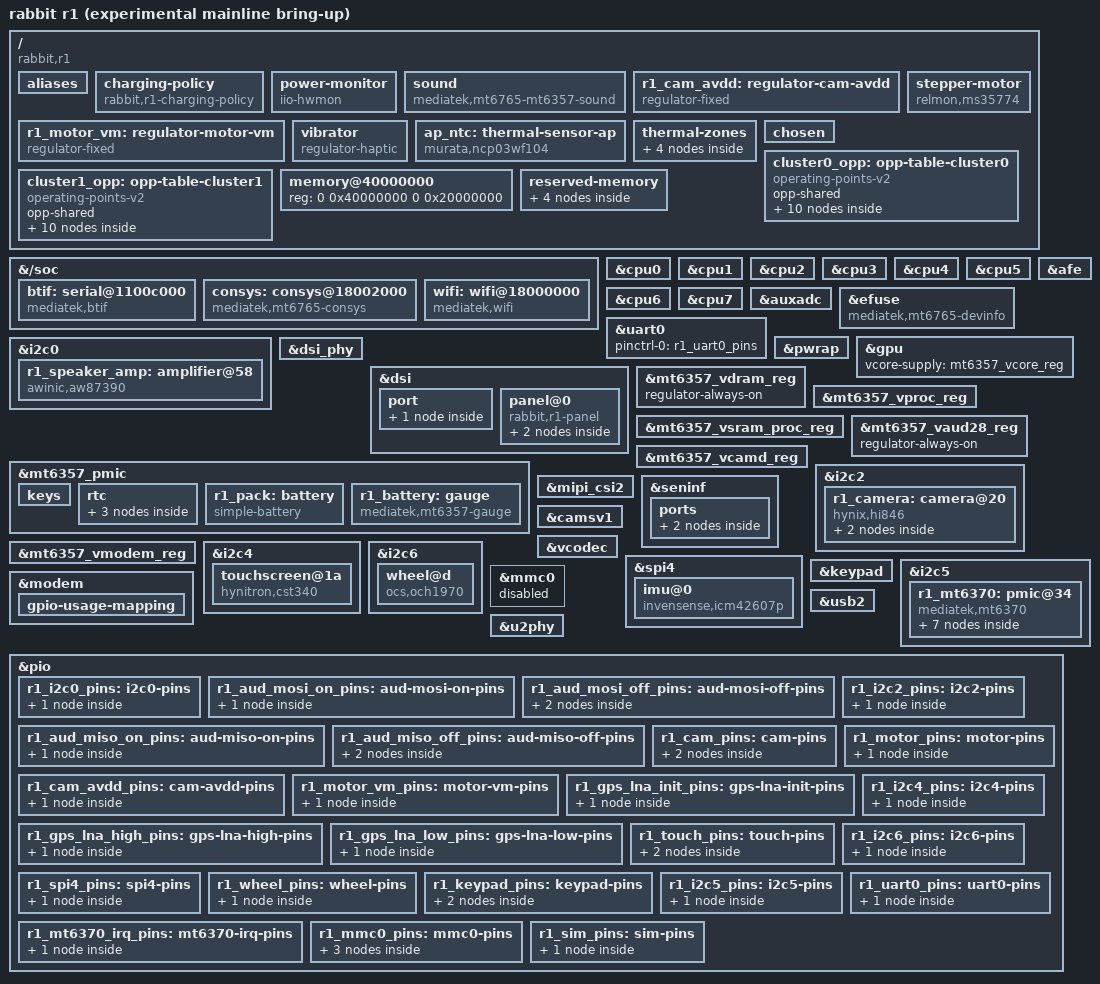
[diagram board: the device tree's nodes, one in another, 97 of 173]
// SPDX-License-Identifier: (GPL-2.0-only OR MIT)
/*
 * Experimental rabbit r1 bring-up tree. NOT hardware validated.
 * Board wiring: rabbit-hmi-oss r1 source and RabbitOS v0.8.293 DT/DTBO.
 * Pin groups follow the MT6765 port's Nokia ROO example where the SoC
 * muxes agree with Rabbit's gpio_init_default table.
 *
 * The stock loader must populate actual RAM and firmware carve-outs.
 * The memory entry below is the stock DT's 512 MiB placeholder, NOT an
 * assertion that the device has only 512 MiB. Inspect the live FDT before
 * relying on it. Do not apply the stock vendor overlay to this tree.
 */

/dts-v1/;

#include <dt-bindings/gpio/gpio.h>
#include <dt-bindings/iio/adc/mediatek,mt6357-auxadc.h>
#include <dt-bindings/iio/adc/mediatek,mt6370_adc.h>
#include <dt-bindings/input/input.h>
#include <dt-bindings/pinctrl/mediatek,mt6765-pinfunc.h>
#include "mt6765.dtsi"
#include "mt6357.dtsi"

/ {
	model = "rabbit r1 (experimental mainline bring-up)";
	compatible = "rabbit,r1", "mediatek,mt6765";
	chassis-type = "handset";

	aliases {
		i2c4 = &i2c4;
		i2c5 = &i2c5;
		mmc0 = &mmc0;
	};

	charging-policy {
		compatible = "rabbit,r1-charging-policy";
		charger-supply = <&r1_charger>;
		battery-supply = <&r1_battery>;
		usb-gadget-supply = <&usb2>;
		/* Experimental, source-backed policy; physical charging is untested. */
	};

	power-monitor {
		compatible = "iio-hwmon";
		io-channels = <&r1_mt6370_adc MT6370_CHAN_VBUSDIV5>,
			      <&r1_mt6370_adc MT6370_CHAN_VSYS>,
			      <&r1_mt6370_adc MT6370_CHAN_VBAT>,
			      <&r1_mt6370_adc MT6370_CHAN_IBUS>,
			      <&r1_mt6370_adc MT6370_CHAN_IBAT>,
			      <&r1_mt6370_adc MT6370_CHAN_TEMP_JC>;
	};

	/*
	 * Stock audio: MT6765 AFE -> MTKAIF -> MT6357 codec. The speaker is an
	 * AW87390 class-K amplifier (I2C0 0x58) on the MT6357 line output; the
	 * stock codec driver turns its "Music" profile on with the LOL path.
	 * No 3.5 mm jack: MT6357 headphone outputs and ACCDET are unused.
	 */
	sound {
		compatible = "mediatek,mt6765-mt6357-sound";
		model = "rabbit-r1";
		mediatek,platform = <&afe>;
		mediatek,speaker-amplifier = <&r1_speaker_amp>;
		pinctrl-names = "aud_mosi_off", "aud_mosi_on",
				"aud_miso_off", "aud_miso_on";
		pinctrl-0 = <&r1_aud_mosi_off_pins>;
		pinctrl-1 = <&r1_aud_mosi_on_pins>;
		pinctrl-2 = <&r1_aud_miso_off_pins>;
		pinctrl-3 = <&r1_aud_miso_on_pins>;
	};

	/*
	 * Stock imgsensor powers the main camera's AVDD from an external
	 * 2.8 V LDO enabled by GPIO165 (cam0_vcama_on), not from MT6357
	 * VCAMA. The stock sequence waits 5 ms after each rail.
	 */
	r1_cam_avdd: regulator-cam-avdd {
		compatible = "regulator-fixed";
		regulator-name = "cam-avdd";
		regulator-min-microvolt = <2800000>;
		regulator-max-microvolt = <2800000>;
		gpio = <&pio 165 GPIO_ACTIVE_HIGH>;
		enable-active-high;
		startup-delay-us = <5000>;
		pinctrl-names = "default";
		pinctrl-0 = <&r1_cam_avdd_pins>;
	};

	/*
	 * Camera rotation ("rabbit eye"): MS35774 stepper driver. Stock
	 * step_motor_ms35774 switches the motor supply with GPIO163 and waits
	 * 10 ms before enabling the outputs; PDN is held low and MS1/MS2 at
	 * high/low throughout.
	 */
	r1_motor_vm: regulator-motor-vm {
		compatible = "regulator-fixed";
		regulator-name = "motor-vm";
		gpio = <&pio 163 GPIO_ACTIVE_HIGH>;
		enable-active-high;
		startup-delay-us = <10000>;
		pinctrl-names = "default";
		pinctrl-0 = <&r1_motor_vm_pins>;
	};

	stepper-motor {
		compatible = "relmon,ms35774";
		vm-supply = <&r1_motor_vm>;
		enable-gpios = <&pio 166 GPIO_ACTIVE_LOW>;
		dir-gpios = <&pio 167 GPIO_ACTIVE_HIGH>;
		step-gpios = <&pio 168 GPIO_ACTIVE_HIGH>;
		powerdown-gpios = <&pio 164 GPIO_ACTIVE_HIGH>;
		mode-gpios = <&pio 171 GPIO_ACTIVE_HIGH>,
			     <&pio 170 GPIO_ACTIVE_HIGH>;
		pinctrl-names = "default";
		pinctrl-0 = <&r1_motor_pins>;
	};

	/*
	 * Stock drives the motor from VIBR at 2.3 - 3.2 V (regulator-vibrator);
	 * VIBR's steps in that range are 2.8 and 3.0 V.
	 */
	vibrator {
		compatible = "regulator-haptic";
		haptic-supply = <&mt6357_vibr_reg>;
		min-microvolt = <2800000>;
		max-microvolt = <3000000>;
	};

	/*
	 * Board NTC next to the SoC on AUXADC channel 0, the stock "mtktsAP"
	 * sensor: a 100 kOhm NCP15WF104F03RC to ground under a 390 kOhm pull-up
	 * to 1.8 V (thermal.conf tzbts_param: PUP_R 390000, PUP_VOLT 1800,
	 * NTC_TABLE 7; DT thermal-sensor1 on auxadc channel 0). The NCP03WF104
	 * is the same WF104 part in a smaller package; the driver's table for it
	 * matches the stock table 7 entry for entry.
	 */
	ap_ntc: thermal-sensor-ap {
		compatible = "murata,ncp03wf104";
		io-channels = <&auxadc 0>;
		pullup-uv = <1800000>;
		pullup-ohm = <390000>;
		pulldown-ohm = <0>;
		#thermal-sensor-cells = <0>;
	};

	thermal-zones {
		/*
		 * The stock policy limits charging from 45 C here and turns the
		 * camera off from 53 C. These trips only report the crossings
		 * to userspace: the reading is not validated on hardware, so
		 * nothing in the kernel acts on it yet.
		 */
		ap_ntc_thermal: ap-ntc-thermal {
			polling-delay-passive = <1000>;
			polling-delay = <2000>;
			thermal-sensors = <&ap_ntc>;

			trips {
				ap_ntc_warm: trip-warm {
					temperature = <45000>;
					hysteresis = <2000>;
					type = "passive";
				};

				ap_ntc_hot: trip-hot {
					temperature = <53000>;
					hysteresis = <2000>;
					type = "passive";
				};
			};
		};
	};

	chosen {
		stdout-path = "serial0:921600n8";
		/*
		 * The stock ATF offers PSCI SYSTEM_SUSPEND, but it runs SPM
		 * firmware that only the stock kernel hands over: sleep to idle.
		 */
		bootargs = "earlycon=uart8250,mmio32,0x11002000 console=ttyS0,921600n8 clk_ignore_unused regulator_ignore_unused mem_sleep_default=s2idle";
	};

	/*
	 * CPU DVFS. Vproc (MT6357 VPROC) and Vsram_proc feed both clusters and
	 * the CCI. Pairs are the stock R1 kernel's CPU level 10 tables: efuse
	 * segment (devinfo word 30, efuse_segment_cell @0x78) reads 0x24 here,
	 * which _mt_cpufreq_get_cpu_level maps to level 10 ("65X"). Tables in
	 * out/stock-kernel.elf: L 0xffffff80097d4498, LL 0xffffff80097d4a18,
	 * CCI 0xffffff80097d4f98 (opp_tbls at 0xffffff80097d5018).
	 *
	 * LK leaves L 1500 MHz, LL 920 MHz and CCI 600 MHz at 0.800 V. CCI is
	 * not scaled; the stock CCI table needs 0.8125 V for 600 MHz, so no OPP
	 * below 0.8125 V is listed. OPPs above 0.85 V are turbo-mode: they stay
	 * unused until /sys/devices/system/cpu/cpufreq/boost is set to 1, as
	 * the thermal throttling in mt6765.dtsi is not validated on hardware.
	 */
	cluster0_opp: opp-table-cluster0 {
		compatible = "operating-points-v2";
		opp-shared;

		opp-1617000000 {
			opp-hz = /bits/ 64 <1617000000>;
			opp-microvolt = <812500>;
		};

		opp-1750000000 {
			opp-hz = /bits/ 64 <1750000000>;
			opp-microvolt = <850000>;
		};

		opp-1803000000 {
			opp-hz = /bits/ 64 <1803000000>;
			opp-microvolt = <893750>;
			turbo-mode;
		};

		opp-1856000000 {
			opp-hz = /bits/ 64 <1856000000>;
			opp-microvolt = <937500>;
			turbo-mode;
		};

		opp-1909000000 {
			opp-hz = /bits/ 64 <1909000000>;
			opp-microvolt = <975000>;
			turbo-mode;
		};

		opp-1962000000 {
			opp-hz = /bits/ 64 <1962000000>;
			opp-microvolt = <1018750>;
			turbo-mode;
		};

		opp-2015000000 {
			opp-hz = /bits/ 64 <2015000000>;
			opp-microvolt = <1056250>;
			turbo-mode;
		};

		opp-2068000000 {
			opp-hz = /bits/ 64 <2068000000>;
			opp-microvolt = <1100000>;
			turbo-mode;
		};

		opp-2130000000 {
			opp-hz = /bits/ 64 <2130000000>;
			opp-microvolt = <1150000>;
			turbo-mode;
		};

		opp-2200000000 {
			opp-hz = /bits/ 64 <2200000000>;
			opp-microvolt = <1200000>;
			turbo-mode;
		};
	};

	cluster1_opp: opp-table-cluster1 {
		compatible = "operating-points-v2";
		opp-shared;

		opp-948000000 {
			opp-hz = /bits/ 64 <948000000>;
			opp-microvolt = <812500>;
		};

		opp-1050000000 {
			opp-hz = /bits/ 64 <1050000000>;
			opp-microvolt = <850000>;
		};

		opp-1114000000 {
			opp-hz = /bits/ 64 <1114000000>;
			opp-microvolt = <893750>;
			turbo-mode;
		};

		opp-1179000000 {
			opp-hz = /bits/ 64 <1179000000>;
			opp-microvolt = <937500>;
			turbo-mode;
		};

		opp-1244000000 {
			opp-hz = /bits/ 64 <1244000000>;
			opp-microvolt = <975000>;
			turbo-mode;
		};

		opp-1309000000 {
			opp-hz = /bits/ 64 <1309000000>;
			opp-microvolt = <1018750>;
			turbo-mode;
		};

		opp-1374000000 {
			opp-hz = /bits/ 64 <1374000000>;
			opp-microvolt = <1056250>;
			turbo-mode;
		};

		opp-1439000000 {
			opp-hz = /bits/ 64 <1439000000>;
			opp-microvolt = <1100000>;
			turbo-mode;
		};

		opp-1515000000 {
			opp-hz = /bits/ 64 <1515000000>;
			opp-microvolt = <1150000>;
			turbo-mode;
		};

		opp-1600000000 {
			opp-hz = /bits/ 64 <1600000000>;
			opp-microvolt = <1200000>;
			turbo-mode;
		};
	};

	/* LK's /memory lookup accepts this unit address and updates the reg. */
	memory@40000000 {
		device_type = "memory";
		reg = <0 0x40000000 0 0x20000000>;
	};

	/* Dynamic reservations copied from the stock base tree. Their final
	 * addresses, plus loader-added TEE/modem reservations, need live-FDT
	 * verification. Remote processors are not enabled by this board file.
	 */
	reserved-memory {
		#address-cells = <2>;
		#size-cells = <2>;
		ranges;

		reserve-memory-sspm_share {
			compatible = "mediatek,reserve-memory-sspm_share";
			no-map;
			size = <0 0x510000>;
			alignment = <0 0x10000>;
			alloc-ranges = <0 0x40000000 0 0x60000000>;
		};

		reserve-memory-scp_share {
			compatible = "mediatek,reserve-memory-scp_share";
			no-map;
			size = <0 0x300000>;
			alignment = <0 0x1000000>;
			alloc-ranges = <0 0x40000000 0 0x50000000>;
		};

		consys_mem: consys-reserve-memory {
			compatible = "mediatek,consys-reserve-memory";
			no-map;
			size = <0 0x400000>;
			alignment = <0 0x1000000>;
			alloc-ranges = <0 0x40000000 0 0x80000000>;
		};

		wifi_mem: wifi-reserve-memory {
			compatible = "shared-dma-pool";
			no-map;
			size = <0 0x300000>;
			alignment = <0 0x1000000>;
			alloc-ranges = <0 0x40000000 0 0x80000000>;
		};
	};
};

/*
 * Connectivity (WiFi/BT/GPS CONSYS, CONNAC1 "soc1_0") for the vendor
 * WMT/BTIF/gen4m drivers in drivers/staging/mtk-connectivity. Addresses,
 * interrupts and register order follow the stock DT; the "conn" scpsys
 * clock of the vendor kernel is the CONN power domain here.
 */
&{/soc} {
	btif: serial@1100c000 {
		compatible = "mediatek,btif";
		/* BTIF, then the AP DMA Tx and Rx channels it owns */
		reg = <0 0x1100c000 0 0x1000>,
		      <0 0x11000880 0 0x80>,
		      <0 0x11000900 0 0x80>;
		interrupts = <GIC_SPI 112 IRQ_TYPE_LEVEL_LOW>,
			     <GIC_SPI 132 IRQ_TYPE_LEVEL_LOW>,
			     <GIC_SPI 133 IRQ_TYPE_LEVEL_LOW>;
		clocks = <&infracfg CLK_IFR_BTIF>,
			 <&infracfg CLK_IFR_AP_DMA>;
		clock-names = "btifc", "apdmac";
	};

	consys: consys@18002000 {
		compatible = "mediatek,mt6765-consys";
		/*
		 * The driver maps these by index: CONN MCU, TOPRGU, INFRACFG_AO,
		 * SPM, CONN_HIF_ON, TOP_MISC_OFF, CFG_ON, CIRQ, TOP_MISC_ON,
		 * HIF_PDMA, AP_PCCIF4 (unused, empty), INFRA_AO_PERICFG (unused)
		 * and INFRACFG for the bus debug dump. The stock DT stopped one
		 * entry short, which left the debug dump with a NULL base.
		 */
		reg = <0 0x18002000 0 0x1000>,
		      <0 0x10007000 0 0x100>,
		      <0 0x10001000 0 0x1000>,
		      <0 0x10006000 0 0x1000>,
		      <0 0x18007000 0 0x1000>,
		      <0 0x180b1000 0 0x1000>,
		      <0 0x180a3000 0 0x1000>,
		      <0 0x180a5000 0 0x800>,
		      <0 0x180c1000 0 0x1000>,
		      <0 0x18004000 0 0x1000>,
		      <0 0 0 0>,
		      <0 0x1020e000 0 0x1000>,
		      <0 0x1020e000 0 0x1000>;
		interrupts = <GIC_SPI 267 IRQ_TYPE_LEVEL_LOW>,
			     <GIC_SPI 269 IRQ_TYPE_LEVEL_LOW>,
			     <GIC_SPI 270 IRQ_TYPE_EDGE_RISING>;
		power-domains = <&spm MT6765_POWER_DOMAIN_CONN>;
		memory-region = <&consys_mem>;
		/*
		 * WMT drives the external GPS LNA enable through these states
		 * while the GPS function is on. The driver takes the LNA pin
		 * number from the first state after "default".
		 */
		pinctrl-names = "default", "gps_lna_state_init",
				"gps_lna_state_oh", "gps_lna_state_ol";
		pinctrl-0 = <&r1_gps_lna_init_pins>;
		pinctrl-1 = <&r1_gps_lna_init_pins>;
		pinctrl-2 = <&r1_gps_lna_high_pins>;
		pinctrl-3 = <&r1_gps_lna_low_pins>;
		pmic = <&mt6357_pmic>;
		vcn18-supply = <&mt6357_vcn18_reg>;
		vcn28-supply = <&mt6357_vcn28_reg>;
		vcn33_bt-supply = <&mt6357_vcn33_bt_reg>;
		vcn33_wifi-supply = <&mt6357_vcn33_wifi_reg>;
	};

	wifi: wifi@18000000 {
		compatible = "mediatek,wifi";
		reg = <0 0x18000000 0 0x100000>;
		interrupts = <GIC_SPI 268 IRQ_TYPE_LEVEL_LOW>;
		memory-region = <&wifi_mem>;
	};
};

&cpu0 {
	clocks = <&mcucfg CLK_MCU_MP0_SEL>,
		 <&topckgen CLK_TOP_ARMPLL_DIVIDER_PLL1_EN>;
	clock-names = "cpu", "intermediate";
	operating-points-v2 = <&cluster0_opp>;
	proc-supply = <&mt6357_vproc_reg>;
	sram-supply = <&mt6357_vsram_proc_reg>;
};

&cpu1 {
	clocks = <&mcucfg CLK_MCU_MP0_SEL>,
		 <&topckgen CLK_TOP_ARMPLL_DIVIDER_PLL1_EN>;
	clock-names = "cpu", "intermediate";
	operating-points-v2 = <&cluster0_opp>;
	proc-supply = <&mt6357_vproc_reg>;
	sram-supply = <&mt6357_vsram_proc_reg>;
};

&cpu2 {
	clocks = <&mcucfg CLK_MCU_MP0_SEL>,
		 <&topckgen CLK_TOP_ARMPLL_DIVIDER_PLL1_EN>;
	clock-names = "cpu", "intermediate";
	operating-points-v2 = <&cluster0_opp>;
	proc-supply = <&mt6357_vproc_reg>;
	sram-supply = <&mt6357_vsram_proc_reg>;
};

&cpu3 {
	clocks = <&mcucfg CLK_MCU_MP0_SEL>,
		 <&topckgen CLK_TOP_ARMPLL_DIVIDER_PLL1_EN>;
	clock-names = "cpu", "intermediate";
	operating-points-v2 = <&cluster0_opp>;
	proc-supply = <&mt6357_vproc_reg>;
	sram-supply = <&mt6357_vsram_proc_reg>;
};

&cpu4 {
	clocks = <&mcucfg CLK_MCU_MP1_SEL>,
		 <&topckgen CLK_TOP_ARMPLL_DIVIDER_PLL1_EN>;
	clock-names = "cpu", "intermediate";
	operating-points-v2 = <&cluster1_opp>;
	proc-supply = <&mt6357_vproc_reg>;
	sram-supply = <&mt6357_vsram_proc_reg>;
};

&cpu5 {
	clocks = <&mcucfg CLK_MCU_MP1_SEL>,
		 <&topckgen CLK_TOP_ARMPLL_DIVIDER_PLL1_EN>;
	clock-names = "cpu", "intermediate";
	operating-points-v2 = <&cluster1_opp>;
	proc-supply = <&mt6357_vproc_reg>;
	sram-supply = <&mt6357_vsram_proc_reg>;
};

&cpu6 {
	clocks = <&mcucfg CLK_MCU_MP1_SEL>,
		 <&topckgen CLK_TOP_ARMPLL_DIVIDER_PLL1_EN>;
	clock-names = "cpu", "intermediate";
	operating-points-v2 = <&cluster1_opp>;
	proc-supply = <&mt6357_vproc_reg>;
	sram-supply = <&mt6357_vsram_proc_reg>;
};

&cpu7 {
	clocks = <&mcucfg CLK_MCU_MP1_SEL>,
		 <&topckgen CLK_TOP_ARMPLL_DIVIDER_PLL1_EN>;
	clock-names = "cpu", "intermediate";
	operating-points-v2 = <&cluster1_opp>;
	proc-supply = <&mt6357_vproc_reg>;
	sram-supply = <&mt6357_vsram_proc_reg>;
};

&auxadc {
	status = "okay";
};

/*
 * The eFuse controller reads as zero once the secure boot chain has run;
 * serve the cells (thermal calibration, socinfo) from LK's devinfo copy.
 */
&efuse {
	compatible = "mediatek,mt6765-devinfo";
};

&uart0 {
	pinctrl-names = "default";
	pinctrl-0 = <&r1_uart0_pins>;
	status = "okay";
};

&pwrap {
	status = "okay";
};

&afe {
	status = "okay";
};

&i2c0 {
	pinctrl-names = "default";
	pinctrl-0 = <&r1_i2c0_pins>;
	/* Stock runs 400 kHz open drain; standard speed for bring-up. */
	clock-frequency = <100000>;
	status = "okay";

	/* Stock aw87xxx_pa@58, dev_index 0; its ACF names the part AW87390. */
	r1_speaker_amp: amplifier@58 {
		compatible = "awinic,aw87390";
		reg = <0x58>;
		#sound-dai-cells = <0>;
		awinic,audio-channel = <0>;
	};
};

&gpu {
	vcore-supply = <&mt6357_vcore_reg>;
	status = "okay";
};

&dsi_phy {
	status = "okay";
};

&dsi {
	status = "okay";

	port {
		r1_dsi_out: endpoint {
			remote-endpoint = <&r1_panel_in>;
		};
	};

	panel@0 {
		compatible = "rabbit,r1-panel";
		reg = <0>;
		reset-gpios = <&pio 45 GPIO_ACTIVE_LOW>;
		backlight = <&r1_backlight>;

		port {
			r1_panel_in: endpoint {
				remote-endpoint = <&r1_dsi_out>;
			};
		};
	};
};

&mt6357_pmic {
	interrupt-controller;
	interrupt-parent = <&pio>;
	interrupts = <144 IRQ_TYPE_LEVEL_HIGH>;
	#interrupt-cells = <2>;

	/*
	 * Stock: only PWRKEY, the side push-to-talk button, as KEY_POWER;
	 * home key commented out. Long-press PMIC reset on PWRKEY, delay 0.
	 */
	keys {
		mediatek,long-press-mode = <1>;
		power-off-time-sec = <0>;

		/delete-node/ key-home;
	};

	rtc {
		nvmem-layout {
			compatible = "fixed-layout";
			#address-cells = <1>;
			#size-cells = <1>;

			/* Raw stock retained bytes; neither is a validated SOC seed. */
			r1_fg_init: initialization@0 {
				reg = <0 1>;
			};

			r1_fg_soc: state-of-charge@1 {
				reg = <1 1>;
			};
		};
	};

	/*
	 * Stock battery_cv is 4.4 V (a high-voltage cell) and the factory
	 * 25 C profile's Qmax is 1010 mAh; the pack is rated 1000 mAh. Alert
	 * temperatures are the stock 0-55 C charging envelope. Charging
	 * limits are the charging policy's, not these.
	 */
	r1_pack: battery {
		compatible = "simple-battery";
		device-chemistry = "lithium-ion";
		charge-full-design-microamp-hours = <1000000>;
		voltage-max-design-microvolt = <4400000>;
		alert-celsius = <0 55>;
	};

	r1_battery: gauge {
		compatible = "mediatek,mt6357-gauge";
		power-supplies = <&r1_charger>;
		monitored-battery = <&r1_pack>;
		/* Stock R_FG_VALUE=10 mOhm, CAR_TUNE_VALUE=100 percent. */
		shunt-resistor-micro-ohms = <10000>;
		mediatek,current-gain-permille = <1000>;
		/* Stock battery voltage is ISENSE, not BATADC. */
		io-channels = <&pmic_adc MT6357_AUXADC_ISENSE>,
			      <&pmic_adc MT6357_AUXADC_BAT_TEMP>,
			      <&pmic_adc MT6357_AUXADC_VBIF>;
		io-channel-names = "battery-voltage", "battery-thermistor", "thermistor-reference";
		mediatek,thermistor-pullup-ohms = <16900>;
		mediatek,thermistor-series-micro-ohms = <10000>;
		/* Active stock 10 kOhm NTC table, also present in v0.8.293's kernel. */
		mediatek,thermistor-resistance-table =
			<(-40000) 195652>, <(-35000) 148171>, <(-30000) 113347>,
			<(-25000) 87559>, <(-20000) 68237>, <(-15000) 53650>,
			<(-10000) 42506>, <(-5000) 33892>, <0 27219>,
			<5000 22021>, <10000 17926>, <15000 14674>,
			<20000 12081>, <25000 10000>, <30000 8315>,
			<35000 6948>, <40000 5834>, <45000 4917>,
			<50000 4161>, <55000 3535>, <60000 3014>;
	};
};

&mt6357_vdram_reg {
	regulator-always-on;
};

/* Stock limits: 1.2 V max (vendor MAX_VPROC_VOLT/MAX_VSRAM_VOLT); LK level as floor. */
&mt6357_vproc_reg {
	regulator-min-microvolt = <800000>;
	regulator-max-microvolt = <1200000>;
};

&mt6357_vsram_proc_reg {
	regulator-min-microvolt = <900000>;
	regulator-max-microvolt = <1200000>;
};

/*
 * The MT6357 codec is an MFD cell without a DT node, so its vaud28 supply
 * resolves to a dummy regulator. Keep the real rail up for the codec.
 */
&mt6357_vaud28_reg {
	regulator-always-on;
};

/* Stock hi846 power table: DVDD 1.2 V from VCAMD, DOVDD 1.8 V from VCAMIO. */
&mt6357_vcamd_reg {
	regulator-min-microvolt = <1200000>;
	regulator-max-microvolt = <1200000>;
};

&i2c2 {
	pinctrl-names = "default";
	pinctrl-0 = <&r1_i2c2_pins>;
	/* Stock runs 400 kHz open drain; standard speed for bring-up. */
	clock-frequency = <100000>;
	status = "okay";

	/*
	 * Main (and only) camera. Stock imgsensor probes hi846_mipi_raw at
	 * 8-bit write ID 0x40, i.e. 7-bit 0x20; the stock DT's camera_main@1a
	 * reg is not used by that driver. PDN (GPIO97) drives XSHUTDOWN and
	 * RST (GPIO101) drives RESETB, both high when the sensor runs. Stock
	 * MCLK is 24 MHz, so the PLL settings here yield 96% of the nominal
	 * 25 MHz link frequencies.
	 */
	r1_camera: camera@20 {
		compatible = "hynix,hi846";
		reg = <0x20>;
		pinctrl-names = "default";
		pinctrl-0 = <&r1_cam_pins>;
		clocks = <&topckgen CLK_TOP_CAMTG_SEL>;
		assigned-clocks = <&topckgen CLK_TOP_CAMTG_SEL>;
		assigned-clock-parents = <&topckgen CLK_TOP_USB20_192M_D8>;
		vdda-supply = <&r1_cam_avdd>;
		vddd-supply = <&mt6357_vcamd_reg>;
		vddio-supply = <&mt6357_vcamio_reg>;
		reset-gpios = <&pio 101 GPIO_ACTIVE_LOW>;
		shutdown-gpios = <&pio 97 GPIO_ACTIVE_LOW>;
		/* Mounted a quarter turn counter-clockwise to the display. */
		rotation = <90>;

		port {
			r1_camera_out: endpoint {
				data-lanes = <1 2 3 4>;
				link-frequencies = /bits/ 64 <80000000 200000000>;
				remote-endpoint = <&r1_seninf_csi2_in>;
			};
		};
	};
};

/*
 * The stock camera configuration (libcameracustom) puts the main sensor
 * on MIPI port CSI2, which the HAL maps to SENINF5 and the CSI2A/B
 * receivers at 0x11c14000/0x11c15000.
 */
&mipi_csi2 {
	status = "okay";
};

&seninf {
	status = "okay";

	ports {
		port@2 {
			/*
			 * 4D1C: clock on CSI2A_L2, data lanes 0-3 on CSI2A_L1,
			 * CSI2B_L0, CSI2A_L0 and CSI2B_L1 (MediaTek default
			 * ball-out, as hardcoded in the CSI PHY driver).
			 */
			r1_seninf_csi2_in: endpoint {
				clock-lanes = <2>;
				data-lanes = <1 3 0 4>;
				remote-endpoint = <&r1_camera_out>;
			};
		};
	};
};

&camsv1 {
	status = "okay";
};

&vcodec {
	status = "okay";
};

/*
 * MD1 core rail. The stock modem driver sets it to 0.8 V before every
 * modem power on and never switches it off; do the same from boot.
 */
&mt6357_vmodem_reg {
	regulator-min-microvolt = <800000>;
	regulator-max-microvolt = <800000>;
	regulator-always-on;
};

&i2c4 {
	pinctrl-names = "default";
	pinctrl-0 = <&r1_i2c4_pins>;
	clock-frequency = <100000>;
	/* Experimental: stock AP channel and touch wiring, not board-tested. */
	status = "okay";

	touchscreen@1a {
		/*
		 * This r1 carries the stock driver's fallback controller: a CST3xx
		 * at 0x1a answering the 0xd1xx info and 0xd0xx report registers.
		 */
		compatible = "hynitron,cst340";
		reg = <0x1a>;
		pinctrl-names = "default";
		pinctrl-0 = <&r1_touch_pins>;
		interrupt-parent = <&pio>;
		interrupts = <0 IRQ_TYPE_EDGE_FALLING>;
		reset-gpios = <&pio 174 GPIO_ACTIVE_LOW>;
		touchscreen-size-x = <480>;
		touchscreen-size-y = <640>;
	};
};

&i2c6 {
	pinctrl-names = "default";
	pinctrl-0 = <&r1_i2c6_pins>;
	/* Stock runs 400 kHz; standard speed for bring-up like I2C4/5. */
	clock-frequency = <100000>;
	status = "okay";

	/* Stock och1970@0d: Hall sensor under the scroll wheel, polled. */
	wheel@d {
		compatible = "ocs,och1970";
		reg = <0x0d>;
		pinctrl-names = "default";
		pinctrl-0 = <&r1_wheel_pins>;
		reset-gpios = <&pio 173 GPIO_ACTIVE_LOW>;
	};
};

/*
 * Stock routes the ICM-42607 IMU through the SCP sensor hub: GPIO13-16 run
 * as SCP_SPI0 (mode 3) and the SCP firmware's icm4n607 driver talks SPI to
 * it. The same pads carry the AP's SPI4 in mode 2, so the AP drives the IMU
 * directly. The interrupt line is not known, so the IMU is polled through
 * an IIO trigger. The supplies follow the MediaTek reference sensor wiring
 * (VIO28 core, VIO18 I/O); both are on from LK and not traced on the board.
 */
&spi4 {
	pinctrl-names = "default";
	pinctrl-0 = <&r1_spi4_pins>;
	/* spi-mt65xx refuses to probe MT6765 controllers without it. */
	mediatek,pad-select = <0>;
	status = "okay";

	imu@0 {
		compatible = "invensense,icm42607p";
		reg = <0>;
		spi-max-frequency = <10000000>;
		vdd-supply = <&mt6357_vio28_reg>;
		vddio-supply = <&mt6357_vio18_reg>;
	};
};

/*
 * Stock mtk-kpd maps hardware key 1 (row 0, column 1) to KEY_POWER. Keys
 * 8, 17 and 71 sit in column 8, which is the PMIC's and has no pin here.
 */
&keypad {
	pinctrl-names = "default";
	pinctrl-0 = <&r1_keypad_pins>;
	keypad,num-rows = <1>;
	keypad,num-columns = <2>;
	linux,keymap = <MATRIX_KEY(0, 1, KEY_POWER)>;
	/* Stock KP_DEBOUNCE 1024 at 32 ticks per ms. */
	debounce-delay-ms = <32>;
	wakeup-source;
	status = "okay";
};

&i2c5 {
	pinctrl-names = "default";
	pinctrl-0 = <&r1_i2c5_pins>;
	/* Keep the stock electrical mode, at standard speed for bring-up. */
	mediatek,use-push-pull;
	clock-frequency = <100000>;
	status = "okay";

	r1_mt6370: pmic@34 {
		compatible = "mediatek,mt6370";
		reg = <0x34>;
		pinctrl-names = "default";
		pinctrl-0 = <&r1_mt6370_irq_pins>;
		interrupts-extended = <&pio 11 IRQ_TYPE_EDGE_FALLING>;
		interrupt-controller;
		#interrupt-cells = <1>;

		r1_mt6370_adc: adc {
			compatible = "mediatek,mt6370-adc";
			#io-channel-cells = <1>;
		};

		/* MFD creates absent children too: explicitly gate unfinished ones. */
		r1_charger: charger {
			compatible = "mediatek,mt6370-charger";
			interrupts = <68>, <48>, <6>;
			interrupt-names = "uvp_d_evt", "attach_i", "mivr";
			io-channels = <&r1_mt6370_adc MT6370_CHAN_IBUS>;
			richtek,managed-charging;
			status = "okay";
		};

		r1_backlight: backlight {
			compatible = "mediatek,mt6370-backlight";
			mediatek,bled-channel-use = /bits/ 8 <15>;
			mediatek,bled-ovp-microvolt = <29000000>;
			mediatek,bled-ocp-microamp = <1500000>;
			max-brightness = <512>;
			default-brightness = <256>;
		};

		tcpc {
			compatible = "mediatek,mt6370-tcpc";
			interrupts-extended = <&pio 41 IRQ_TYPE_EDGE_FALLING>;
			status = "disabled";
		};

		indicator {
			compatible = "mediatek,mt6370-indicator";
			#address-cells = <1>;
			#size-cells = <0>;
			status = "disabled";
		};

		flashlight {
			compatible = "mediatek,mt6370-flashlight";
			#address-cells = <1>;
			#size-cells = <0>;
			status = "disabled";
		};

		/* Register the rails without requesting voltage or enable changes. */
		regulators {
		};
	};
};

&mmc0 {
	pinctrl-names = "default", "state_uhs";
	pinctrl-0 = <&r1_mmc0_pins>;
	/* The host requires both states, including at legacy/high-speed timing. */
	pinctrl-1 = <&r1_mmc0_pins>;
	bus-width = <8>;
	/* Start at legacy/high-speed timing; HS200/HS400 tuning is untested. */
	max-frequency = <52000000>;
	cap-mmc-highspeed;
	non-removable;
	no-sd;
	no-sdio;
	vmmc-supply = <&mt6357_vemc_reg>;
	/* VIO18 is inferred from the SoC reference; verify on the board. */
	vqmmc-supply = <&mt6357_vio18_reg>;
	/* MT6765 port reports partial eMMC support. First boot uses initramfs.
	 * Enable only for an instrumented storage test after PMIC validation.
	 */
	status = "disabled";
};

/*
 * Only the r1-md-probe bring-up module binds here, and only when loaded
 * by hand with stage=1 or stage=2.
 */
&modem {
	pinctrl-names = "default";
	pinctrl-0 = <&r1_sim_pins>;
	vmodem-supply = <&mt6357_vmodem_reg>;
	vcore-supply = <&mt6357_vcore_reg>;
	status = "okay";

	/* stock gpio_usage_mapping; the modem asks for these by name over RPC */
	gpio-usage-mapping {
		GPIO_SIM1_HOT_PLUG = <&pio 47 0>;
		GPIO_SIM2_HOT_PLUG = <&pio 46 0>;
		GPIO_SIM1_SIO = <&pio 40 0>;
		GPIO_SIM1_SRST = <&pio 39 0>;
		GPIO_SIM1_SCLK = <&pio 38 0>;
		GPIO_SIM2_SCLK = <&pio 37 0>;
		GPIO_SIM2_SRST = <&pio 36 0>;
		GPIO_SIM2_SIO = <&pio 35 0>;
	};
};

&usb2 {
	assigned-clocks = <&topckgen CLK_TOP_USB_TOP_SEL>;
	assigned-clock-parents = <&topckgen CLK_TOP_UNIVPLL3_D4>;
	dr_mode = "peripheral";
	status = "okay";
};

&u2phy {
	status = "okay";
};

&pio {
	/* Stock gpio_init_default: GPIO82/83 in mode 1, pulled up. */
	r1_i2c0_pins: i2c0-pins {
		pins-bus {
			pinmux = <PINMUX_GPIO82__FUNC_SDA0>,
				 <PINMUX_GPIO83__FUNC_SCL0>;
			input-enable;
			bias-pull-up;
		};
	};

	/*
	 * MTKAIF to the MT6357. Stock gpio_init_default leaves GPIO136-143
	 * in mode 1; its audio driver parks the clock and data pins as GPIOs
	 * between streams (aud_{clk,dat}_{mosi,miso}_{off,on}).
	 */
	r1_aud_mosi_on_pins: aud-mosi-on-pins {
		pins-aud {
			pinmux = <PINMUX_GPIO136__FUNC_AUD_CLK_MOSI>,
				 <PINMUX_GPIO137__FUNC_AUD_SYNC_MOSI>,
				 <PINMUX_GPIO138__FUNC_AUD_DAT_MOSI0>,
				 <PINMUX_GPIO139__FUNC_AUD_DAT_MOSI1>;
		};
	};

	r1_aud_mosi_off_pins: aud-mosi-off-pins {
		pins-clk {
			pinmux = <PINMUX_GPIO136__FUNC_GPIO136>;
		};

		pins-dat {
			pinmux = <PINMUX_GPIO138__FUNC_GPIO138>,
				 <PINMUX_GPIO139__FUNC_GPIO139>;
			input-enable;
			bias-disable;
		};
	};

	r1_aud_miso_on_pins: aud-miso-on-pins {
		pins-aud {
			pinmux = <PINMUX_GPIO140__FUNC_AUD_CLK_MISO>,
				 <PINMUX_GPIO141__FUNC_AUD_SYNC_MISO>,
				 <PINMUX_GPIO142__FUNC_AUD_DAT_MISO0>,
				 <PINMUX_GPIO143__FUNC_AUD_DAT_MISO1>;
		};
	};

	r1_aud_miso_off_pins: aud-miso-off-pins {
		pins-clk {
			pinmux = <PINMUX_GPIO140__FUNC_GPIO140>;
		};

		pins-dat {
			pinmux = <PINMUX_GPIO142__FUNC_GPIO142>,
				 <PINMUX_GPIO143__FUNC_GPIO143>;
			input-enable;
			bias-disable;
		};
	};

	/* Stock gpio_init_default: GPIO103/104 in mode 1, pulled up. */
	r1_i2c2_pins: i2c2-pins {
		pins-bus {
			pinmux = <PINMUX_GPIO103__FUNC_SCL2>,
				 <PINMUX_GPIO104__FUNC_SDA2>;
			input-enable;
			bias-pull-up;
		};
	};

	/* Stock gpio_init_default: GPIO99 as CMMCLK0, GPIO97/101 as GPIOs. */
	r1_cam_pins: cam-pins {
		pins-mclk {
			pinmux = <PINMUX_GPIO99__FUNC_CMMCLK0>;
		};

		pins-ctrl {
			pinmux = <PINMUX_GPIO97__FUNC_GPIO97>,
				 <PINMUX_GPIO101__FUNC_GPIO101>;
		};
	};

	r1_cam_avdd_pins: cam-avdd-pins {
		pins-en {
			pinmux = <PINMUX_GPIO165__FUNC_GPIO165>;
		};
	};

	r1_motor_vm_pins: motor-vm-pins {
		pins-en {
			pinmux = <PINMUX_GPIO163__FUNC_GPIO163>;
		};
	};

	r1_motor_pins: motor-pins {
		pins-ctrl {
			pinmux = <PINMUX_GPIO164__FUNC_GPIO164>,
				 <PINMUX_GPIO166__FUNC_GPIO166>,
				 <PINMUX_GPIO167__FUNC_GPIO167>,
				 <PINMUX_GPIO168__FUNC_GPIO168>,
				 <PINMUX_GPIO170__FUNC_GPIO170>,
				 <PINMUX_GPIO171__FUNC_GPIO171>;
		};
	};

	/* Stock consys gpslna@0..2: GPIO177, released (input) when GPS is off. */
	r1_gps_lna_init_pins: gps-lna-init-pins {
		pins-lna {
			pinmux = <PINMUX_GPIO177__FUNC_GPIO177>;
			input-enable;
			bias-disable;
		};
	};

	r1_gps_lna_high_pins: gps-lna-high-pins {
		pins-lna {
			pinmux = <PINMUX_GPIO177__FUNC_GPIO177>;
			output-high;
		};
	};

	r1_gps_lna_low_pins: gps-lna-low-pins {
		pins-lna {
			pinmux = <PINMUX_GPIO177__FUNC_GPIO177>;
			output-low;
		};
	};

	r1_i2c4_pins: i2c4-pins {
		pins-bus {
			pinmux = <PINMUX_GPIO105__FUNC_SCL4>,
				 <PINMUX_GPIO106__FUNC_SDA4>;
			input-enable;
		};
	};

	r1_touch_pins: touch-pins {
		pins-irq {
			pinmux = <PINMUX_GPIO0__FUNC_GPIO0>;
			input-enable;
		};

		pins-reset {
			pinmux = <PINMUX_GPIO174__FUNC_GPIO174>;
		};
	};

	r1_i2c6_pins: i2c6-pins {
		pins-bus {
			pinmux = <PINMUX_GPIO161__FUNC_SCL6>,
				 <PINMUX_GPIO162__FUNC_SDA6>;
			input-enable;
		};
	};

	/* Keep the stock gpio_init_default bias: MISO pulled down, the rest none. */
	r1_spi4_pins: spi4-pins {
		pins-spi {
			pinmux = <PINMUX_GPIO13__FUNC_SPI4_MI>,
				 <PINMUX_GPIO14__FUNC_SPI4_CSB>,
				 <PINMUX_GPIO15__FUNC_SPI4_MO>,
				 <PINMUX_GPIO16__FUNC_SPI4_CLK>;
		};
	};

	r1_wheel_pins: wheel-pins {
		pins-reset {
			pinmux = <PINMUX_GPIO173__FUNC_GPIO173>;
		};
	};

	/* Stock gpio_init_default: KPROW0 driven, KPCOL0/1 pulled up. */
	r1_keypad_pins: keypad-pins {
		pins-rows {
			pinmux = <PINMUX_GPIO92__FUNC_KPROW0>;
			output-low;
			bias-disable;
		};

		pins-cols {
			pinmux = <PINMUX_GPIO93__FUNC_KPCOL0>,
				 <PINMUX_GPIO94__FUNC_KPCOL1>;
			input-enable;
			input-schmitt-enable;
			bias-pull-up = <MTK_PUPD_SET_R1R0_10>;
		};
	};

	r1_i2c5_pins: i2c5-pins {
		pins-bus {
			pinmux = <PINMUX_GPIO48__FUNC_SCL5>,
				 <PINMUX_GPIO49__FUNC_SDA5>;
			input-enable;
		};
	};

	r1_mt6370_irq_pins: mt6370-irq-pins {
		pins-irq {
			pinmux = <PINMUX_GPIO11__FUNC_GPIO11>;
			input-enable;
		};
	};

	r1_uart0_pins: uart0-pins {
		pins {
			pinmux = <PINMUX_GPIO95__FUNC_URXD0>,
				 <PINMUX_GPIO96__FUNC_UTXD0>;
		};
	};

	r1_mmc0_pins: mmc0-pins {
		pins-cmd-dat {
			/* LK runs every MSDC0 pin in mode 1; mode 2 permutes the data lines. */
			pinmux = <PINMUX_GPIO123__FUNC_MSDC0_DAT0>,
				 <PINMUX_GPIO128__FUNC_MSDC0_DAT1>,
				 <PINMUX_GPIO125__FUNC_MSDC0_DAT2>,
				 <PINMUX_GPIO132__FUNC_AUX1_MSDC0_DAT3>,
				 <PINMUX_GPIO126__FUNC_MSDC0_DAT4>,
				 <PINMUX_GPIO129__FUNC_MSDC0_DAT5>,
				 <PINMUX_GPIO127__FUNC_MSDC0_DAT6>,
				 <PINMUX_GPIO130__FUNC_AUX1_MSDC0_DAT7>,
				 <PINMUX_GPIO122__FUNC_AUX1_MSDC0_CMD>;
			input-enable;
			drive-strength = <3>;
			bias-pull-up = <MTK_PUPD_SET_R1R0_01>;
		};

		pins-clk {
			pinmux = <PINMUX_GPIO124__FUNC_AUX1_MSDC0_CLK>;
			drive-strength = <3>;
			bias-pull-down = <MTK_PUPD_SET_R1R0_10>;
		};

		pins-rst {
			pinmux = <PINMUX_GPIO133__FUNC_AUX1_MSDC0_RSTB>;
			drive-strength = <3>;
			bias-pull-up = <MTK_PUPD_SET_R1R0_01>;
		};
	};

	/*
	 * Both SIM interfaces and their hot plug inputs belong to the modem.
	 * Stock gpio_init_default puts GPIO35-40 and GPIO46/47 in mode 1 and
	 * sets their pulls; only the function is claimed here.
	 */
	r1_sim_pins: sim-pins {
		pins-sim {
			pinmux = <PINMUX_GPIO35__FUNC_MD1_SIM2_SIO>,
				 <PINMUX_GPIO36__FUNC_MD1_SIM2_SRST>,
				 <PINMUX_GPIO37__FUNC_MD1_SIM2_SCLK>,
				 <PINMUX_GPIO38__FUNC_MD1_SIM1_SCLK>,
				 <PINMUX_GPIO39__FUNC_MD1_SIM1_SRST>,
				 <PINMUX_GPIO40__FUNC_MD1_SIM1_SIO>,
				 <PINMUX_GPIO46__FUNC_MD_INT2_C2K_UIM1_HOT_PLUG>,
				 <PINMUX_GPIO47__FUNC_MD_INT1_C2K_UIM0_HOT_PLUG>;
		};
	};
};
